# ATmega64HVE2 register map
Vendor: Atmel; File version: 1.0
CPU: other r0p0, little endian, no MPU, no FPU, 4 interrupt priority bits
Registers are 8-bit, read-write, reset 0x0 unless marked. A register's access mark holds for its fields unless they carry their own. Offsets are from the block's base; lines under a group give offsets from that group; [hi:lo] are bit positions; {n}, {i} and the like mark numbered series; 'fields as' and 'values as' point back to an identical list; <NAME> marks a mode.

## Memory map
0x00800020 PORTA size 0x3 — I/O Port
0x00800023 PORTB blocks up to offset 0xBA — I/O Port
0x00800035 TC0 blocks up to offset 0x3A — Timer/Counter, 16-bit
0x00800036 TC1 blocks up to offset 0x54 — Timer/Counter, 16-bit
0x0080003B EXINT blocks up to offset 0x32 — External Interrupts
0x0080003E CPU blocks up to offset 0x9B — CPU Registers
0x0080003F EEPROM size 0x4
0x0080004C SPI size 0x3 — Serial Peripheral Interface
0x00800057 BOOT_LOAD size 0x1 — Bootloader
0x00800060 WDT blocks up to offset 0x4 — Watchdog Timer
0x00800062 WAKEUP_TIMER size 0x1
0x008000C0 LINUART size 0xB — Local Interconnect Network
0x008000D1 BANDGAP size 0x4
0x008000E0 ADC size 0x17 — Analog-to-Digital Converter

## Interrupts
0 RESET (CPU) — External Pin, Power-on Reset, Brown-out Reset and Watchdog Reset
1 INT0 (CPU) — External Interrupt 0
2 PCINT0 (CPU) — Pin Change Interrupt 0
3 PCINT1 (CPU) — Pin Change Interrupt 1
4 WDT (CPU) — Watchdog Timeout Interrupt
5 WAKEUP (CPU) — Wakeup Timer Overflow
6 TIMER1_IC (CPU) — Timer 1 Input capture
7 TIMER1_COMPA (CPU) — Timer 1 Compare Match A
8 TIMER1_COMPB (CPU) — Timer 1 Compare Match B
9 TIMER1_OVF (CPU) — Timer 1 overflow
10 TIMER0_IC (CPU) — Timer 0 Input Capture
11 TIMER0_COMPA (CPU) — Timer 0 Compare Match A
12 TIMER0_COMPB (CPU) — Timer 0 Compare Match B
13 TIMER0_OVF (CPU) — Timer 0 Overflow
14 LIN_STATUS (CPU) — LIN Status Interrupt
15 LIN_ERROR (CPU) — LIN Error Interrupt
16 SPI_STC (CPU) — SPI Serial transfer complete
17 VADC_CONV (CPU) — Voltage ADC Instantaneous Conversion Complete
18 VADC_ACC (CPU) — Voltage ADC Accumulated Conversion Complete
19 CADC_CONV (CPU) — C-ADC Instantaneous Conversion Complete
20 CADC_REG_CUR (CPU) — C-ADC Regular Current
21 CADC_ACC (CPU) — C-ADC Accumulated Conversion Complete
22 EE_READY (CPU) — EEPROM Ready
23 SPM (CPU) — SPM Ready
24 PLL (CPU) — PLL Lock Change Interrupt

## BANDGAP
Base 0x008000D1
0x00 BGCSRA — Bandgap Control and Status Register A
  [2:0] BGSC — Band Gap Sample Configuration
0x01 BGCRB — Band Gap Calibration Register B
  [7:0] BGCL — Band Gap Calibration Linear
0x02 BGCRA — Band Gap Calibration Register A
  [7:0] BGCN — Band Gap Calibration Nominal
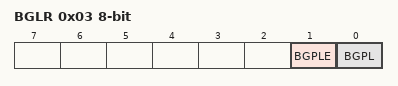
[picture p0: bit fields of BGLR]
0x03 BGLR — Band Gap Lock Register
  [1] BGPLE — Band Gap Lock Enable
  [0] BGPL — Band Gap Lock

## BOOT_LOAD — Bootloader
Base 0x00800057
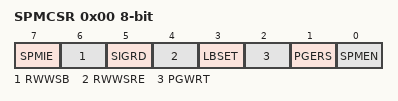
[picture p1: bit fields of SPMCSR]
0x00 SPMCSR — Store Program Memory Control and Status Register
  [7] SPMIE — SPM Interrupt Enable
  [6] RWWSB — Read-While-Write Section Busy
  [5] SIGRD — Signature Row Read
  [4] RWWSRE — Read-While-Write Section Read Enable
  [3] LBSET — Lock Bit Set
  [2] PGWRT — Page Write
  [1] PGERS — Page Erase
  [0] SPMEN — Store Program Memory Enable

## CPU — CPU Registers
Base 0x0080003E
0x00 GPIOR0 — General Purpose IO Register 0
0x0C GPIOR1 — General Purpose IO Register 1
0x0D GPIOR2 — General Purpose IO Register 2
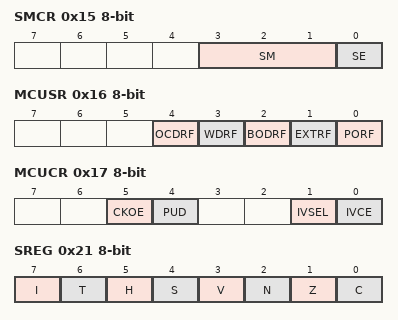
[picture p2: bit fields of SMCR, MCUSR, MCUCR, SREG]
0x15 SMCR — Sleep Mode Control Register
  [3:1] SM — Sleep Mode Select bits
    0=IDLE; 1=ADC; 2=PDOWN (Power Down); 3=PSAVE (Power Save); 6=STDBY (Standby); 7=ESTDBY (Extended Standby)
  [0] SE — Sleep Enable
0x16 MCUSR — MCU Status Register (read-only for debugger)
  [4] OCDRF — OCD Reset Flag
  [3] WDRF — Watchdog Reset Flag
  [2] BODRF — Brown-out Reset Flag
  [1] EXTRF — External Reset Flag
  [0] PORF — Power-on reset flag
0x17 MCUCR — MCU Control Register
  [5] CKOE — Clock Output Enable
  [4] PUD — Pull-up disable
  [1] IVSEL — Interrupt Vector Select
  [0] IVCE — Interrupt Vector Change Enable
0x1F SP 16-bit (reset mask 0xFF) — Stack Pointer
0x21 SREG — Status Register
  [7] I — Global Interrupt Enable
  [6] T — Bit Copy Storage
  [5] H — Half Carry Flag
  [4] S — Sign Bit
  [3] V — Two's Complement Overflow Flag
  [2] N — Negative Flag
  [1] Z — Zero Flag
  [0] C — Carry Flag
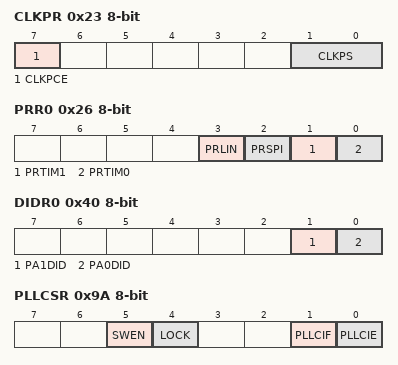
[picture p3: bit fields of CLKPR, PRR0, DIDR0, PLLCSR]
0x23 CLKPR — Clock Prescale Register (read-only for debugger)
  [7] CLKPCE — Clock Prescaler Change Enable
  [1:0] CLKPS — Clock Prescaler Select Bits
0x26 PRR0 — Power Reduction Register 0
  [3] PRLIN — Power Reduction LIN UART Interface
  [2] PRSPI — Power reduction SPI
  [1] PRTIM1 — Power Reduction Timer/Counter1
  [0] PRTIM0 — Power Reduction Timer/Counter0
0x28 SOSCCALA — Slow Oscillator Calibration Register A
0x29 SOSCCALB — Oscillator Calibration Register B
0x40 DIDR0 — Digital Input Disable Register
  [1] PA1DID — When this bit is written logic one, the digital input buffer of the corresponding V_ADC pin is disabled.
  [0] PA0DID — When this bit is written logic one, the digital input buffer of the corresponding V_ADC pin is disabled.
0x9A PLLCSR — PLL Control and Status Register
  [5] SWEN — PLL Software Enable
  [4] LOCK — PLL Lock
  [1] PLLCIF — PLL Lock Change Interrupt Flag
  [0] PLLCIE — PLL Lock Change Interrupt Enable
